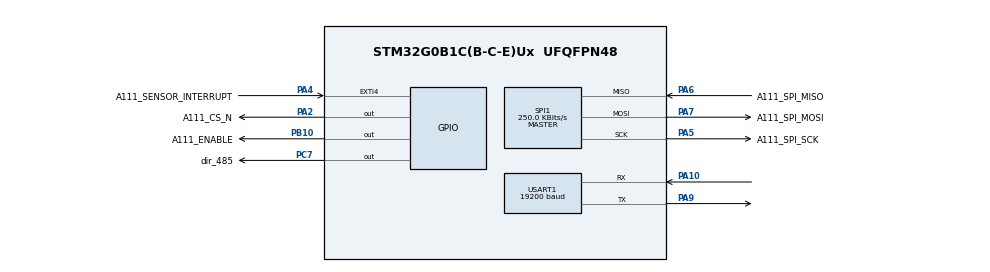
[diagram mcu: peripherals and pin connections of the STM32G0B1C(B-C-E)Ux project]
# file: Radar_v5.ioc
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Mcu.Family=STM32G0
Mcu.Name=STM32G0B1C(B-C-E)Ux
Mcu.Package=UFQFPN48
NVIC.TIM15_IRQn=true\:3\:0\:true\:false\:true\:true\:true
NVIC.USART1_IRQn=true\:0\:0\:false\:false\:true\:true\:true
PA10.Mode=Asynchronous
PA10.Signal=USART1_RX
PA13.Mode=Serial_Wire
PA13.Signal=SYS_SWDIO
PA14-BOOT0.Mode=Serial_Wire
PA14-BOOT0.Signal=SYS_SWCLK
PA2.GPIO_Label=A111_CS_N
PA2.Signal=GPIO_Output
PA4.GPIO_Label=A111_SENSOR_INTERRUPT
PA4.Signal=GPXTI4
PA5.GPIO_Label=A111_SPI_SCK
PA5.Mode=Full_Duplex_Master
PA5.Signal=SPI1_SCK
PA6.GPIO_Label=A111_SPI_MISO
PA6.Mode=Full_Duplex_Master
PA6.Signal=SPI1_MISO
PA7.GPIO_Label=A111_SPI_MOSI
PA7.Mode=Full_Duplex_Master
PA7.Signal=SPI1_MOSI
PA9.GPIO_ModeDefaultPP=GPIO_MODE_AF_OD
PA9.Mode=Asynchronous
PA9.Signal=USART1_TX
PB10.GPIO_Label=A111_ENABLE
PB10.Signal=GPIO_Output
PC7.GPIO_Label=dir_485
PC7.GPIO_ModeDefaultOutputPP=GPIO_MODE_OUTPUT_OD
PC7.Signal=GPIO_Output
PF0-OSC_IN\ (PF0).Mode=HSE-External-Oscillator
PF0-OSC_IN\ (PF0).Signal=RCC_OSC_IN
PF1-OSC_OUT\ (PF1).Mode=HSE-External-Oscillator
PF1-OSC_OUT\ (PF1).Signal=RCC_OSC_OUT
ProjectManager.HeapSize=0x200
ProjectManager.StackSize=0x400
ProjectManager.TargetToolchain=STM32CubeIDE
RCC.ADCFreq_Value=64000000
RCC.AHBFreq_Value=64000000
RCC.CortexFreq_Value=64000000
RCC.EXTERNAL_CLOCK_VALUE=48000
RCC.HCLKFreq_Value=64000000
RCC.HSE_VALUE=12000000
RCC.HSI48_VALUE=48000000
RCC.HSI_VALUE=16000000
RCC.LSE_VALUE=32768
RCC.PLLN=16
RCC.PLLR=RCC_PLLR_DIV3
RCC.PLLSourceVirtual=RCC_PLLSOURCE_HSE
RCC.SYSCLKFreq_VALUE=64000000
RCC.SYSCLKSource=RCC_SYSCLKSOURCE_PLLCLK
RCC.USBFreq_Value=48000000
RCC.VCOOutputFreq_Value=192000000
SPI1.BaudRatePrescaler=SPI_BAUDRATEPRESCALER_256
SPI1.CalculateBaudRate=250.0 KBits/s
SPI1.Direction=SPI_DIRECTION_2LINES
SPI1.Mode=SPI_MODE_MASTER
SPI1.VirtualType=VM_MASTER
TIM15.Period=999
TIM15.Prescaler=63999
TIM3.Prescaler=63999
TIM6.Prescaler=63999
USART1.BaudRate=19200
USART1.VirtualMode-Asynchronous=VM_ASYNC
VP_SYS_VS_DBSignals.Mode=DisableDeadBatterySignals
VP_TIM15_VS_ClockSourceINT.Mode=Internal
VP_TIM3_VS_ClockSourceINT.Mode=Internal
VP_TIM6_VS_ClockSourceINT.Mode=Enable_Timer
board=custom

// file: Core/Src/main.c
/* USER CODE BEGIN Header */
/**
  ******************************************************************************
  * @file           : main.c
  * @brief          : Main program body
  ******************************************************************************
  * @attention
  *
  * <h2><center>&copy; Copyright (c) 2022 STMicroelectronics.
  * All rights reserved.</center></h2>
  *
  * This software component is licensed by ST under BSD 3-Clause license,
  * the "License"; You may not use this file except in compliance with the
  * License. You may obtain a copy of the License at:
  *                        opensource.org/licenses/BSD-3-Clause
  *
  ******************************************************************************
  */
/* USER CODE END Header */
#include "main.h"

SPI_HandleTypeDef hspi1;

TIM_HandleTypeDef htim3;
TIM_HandleTypeDef htim6;

void SystemClock_Config(void);
static void MX_GPIO_Init(void);
static void MX_SPI1_Init(void);
static void MX_USART1_UART_Init(void);
static void MX_TIM15_Init(void);
static void MX_TIM3_Init(void);
static void MX_TIM6_Init(void);

int main(void)
{

  /* MCU Configuration--------------------------------------------------------*/

  /* Reset of all peripherals, Initializes the Flash interface and the Systick. */
  HAL_Init();

  /* Configure the system clock */
  SystemClock_Config();

  /* Initialize all configured peripherals */
  MX_GPIO_Init();
  MX_SPI1_Init();
  MX_USART1_UART_Init();
  MX_TIM15_Init();
  MX_TIM3_Init();
  MX_TIM6_Init();
  /* USER CODE BEGIN 2 */
  my_main();
  /* USER CODE END 2 */

  /* Infinite loop */
  while (1)
  {

  }
}

void SystemClock_Config(void)
{
  LL_FLASH_SetLatency(LL_FLASH_LATENCY_2);
  while(LL_FLASH_GetLatency() != LL_FLASH_LATENCY_2)
  {
  }

  /* HSE configuration and activation */
  LL_RCC_HSE_Enable();
  while(LL_RCC_HSE_IsReady() != 1)
  {
  }

  /* Main PLL configuration and activation */
  LL_RCC_PLL_ConfigDomain_SYS(LL_RCC_PLLSOURCE_HSE, LL_RCC_PLLM_DIV_1, 16, LL_RCC_PLLR_DIV_3);
  LL_RCC_PLL_Enable();
  LL_RCC_PLL_EnableDomain_SYS();
  while(LL_RCC_PLL_IsReady() != 1)
  {
  }

  /* Set AHB prescaler*/
  LL_RCC_SetAHBPrescaler(LL_RCC_SYSCLK_DIV_1);

  /* Sysclk activation on the main PLL */
  LL_RCC_SetSysClkSource(LL_RCC_SYS_CLKSOURCE_PLL);
  while(LL_RCC_GetSysClkSource() != LL_RCC_SYS_CLKSOURCE_STATUS_PLL)
  {
  }

  /* Set APB1 prescaler*/
  LL_RCC_SetAPB1Prescaler(LL_RCC_APB1_DIV_1);
  /* Update CMSIS variable (which can be updated also through SystemCoreClockUpdate function) */
  LL_SetSystemCoreClock(64000000);

   /* Update the time base */
  if (HAL_InitTick (TICK_INT_PRIORITY) != HAL_OK)
  {
    Error_Handler();
  }
  LL_RCC_SetTIMClockSource(LL_RCC_TIM15_CLKSOURCE_PCLK1);
  LL_RCC_SetUSARTClockSource(LL_RCC_USART1_CLKSOURCE_PCLK1);
}

static void MX_SPI1_Init(void)
{

  /* SPI1 parameter configuration*/
  hspi1.Instance = SPI1;
  hspi1.Init.Mode = SPI_MODE_MASTER;
  hspi1.Init.Direction = SPI_DIRECTION_2LINES;
  hspi1.Init.DataSize = SPI_DATASIZE_8BIT;
  hspi1.Init.CLKPolarity = SPI_POLARITY_LOW;
  hspi1.Init.CLKPhase = SPI_PHASE_1EDGE;
  hspi1.Init.NSS = SPI_NSS_SOFT;
  hspi1.Init.BaudRatePrescaler = SPI_BAUDRATEPRESCALER_256;
  hspi1.Init.FirstBit = SPI_FIRSTBIT_MSB;
  hspi1.Init.TIMode = SPI_TIMODE_DISABLE;
  hspi1.Init.CRCCalculation = SPI_CRCCALCULATION_DISABLE;
  hspi1.Init.CRCPolynomial = 7;
  hspi1.Init.CRCLength = SPI_CRC_LENGTH_DATASIZE;
  hspi1.Init.NSSPMode = SPI_NSS_PULSE_ENABLE;
  if (HAL_SPI_Init(&hspi1) != HAL_OK)
  {
    Error_Handler();
  }

}

static void MX_TIM3_Init(void)
{

  TIM_ClockConfigTypeDef sClockSourceConfig = {0};
  TIM_MasterConfigTypeDef sMasterConfig = {0};

  htim3.Instance = TIM3;
  htim3.Init.Prescaler = 63999;
  htim3.Init.CounterMode = TIM_COUNTERMODE_UP;
  htim3.Init.Period = 65535;
  htim3.Init.ClockDivision = TIM_CLOCKDIVISION_DIV1;
  htim3.Init.AutoReloadPreload = TIM_AUTORELOAD_PRELOAD_DISABLE;
  if (HAL_TIM_Base_Init(&htim3) != HAL_OK)
  {
    Error_Handler();
  }
  sClockSourceConfig.ClockSource = TIM_CLOCKSOURCE_INTERNAL;
  if (HAL_TIM_ConfigClockSource(&htim3, &sClockSourceConfig) != HAL_OK)
  {
    Error_Handler();
  }
  sMasterConfig.MasterOutputTrigger = TIM_TRGO_RESET;
  sMasterConfig.MasterSlaveMode = TIM_MASTERSLAVEMODE_DISABLE;
  if (HAL_TIMEx_MasterConfigSynchronization(&htim3, &sMasterConfig) != HAL_OK)
  {
    Error_Handler();
  }

}

static void MX_TIM6_Init(void)
{

  TIM_MasterConfigTypeDef sMasterConfig = {0};

  htim6.Instance = TIM6;
  htim6.Init.Prescaler = 63999;
  htim6.Init.CounterMode = TIM_COUNTERMODE_UP;
  htim6.Init.Period = 65535;
  htim6.Init.AutoReloadPreload = TIM_AUTORELOAD_PRELOAD_DISABLE;
  if (HAL_TIM_Base_Init(&htim6) != HAL_OK)
  {
    Error_Handler();
  }
  sMasterConfig.MasterOutputTrigger = TIM_TRGO_RESET;
  sMasterConfig.MasterSlaveMode = TIM_MASTERSLAVEMODE_DISABLE;
  if (HAL_TIMEx_MasterConfigSynchronization(&htim6, &sMasterConfig) != HAL_OK)
  {
    Error_Handler();
  }

}

static void MX_TIM15_Init(void)
{

  LL_TIM_InitTypeDef TIM_InitStruct = {0};

  /* Peripheral clock enable */
  LL_APB2_GRP1_EnableClock(LL_APB2_GRP1_PERIPH_TIM15);

  /* TIM15 interrupt Init */
  NVIC_SetPriority(TIM15_IRQn, 3);
  NVIC_EnableIRQ(TIM15_IRQn);

  TIM_InitStruct.Prescaler = 63999;
  TIM_InitStruct.CounterMode = LL_TIM_COUNTERMODE_UP;
  TIM_InitStruct.Autoreload = 999;
  TIM_InitStruct.ClockDivision = LL_TIM_CLOCKDIVISION_DIV1;
  TIM_InitStruct.RepetitionCounter = 0;
  LL_TIM_Init(TIM15, &TIM_InitStruct);
  LL_TIM_DisableARRPreload(TIM15);
  LL_TIM_SetClockSource(TIM15, LL_TIM_CLOCKSOURCE_INTERNAL);
  LL_TIM_SetTriggerOutput(TIM15, LL_TIM_TRGO_RESET);
  LL_TIM_DisableMasterSlaveMode(TIM15);

}

static void MX_USART1_UART_Init(void)
{

  LL_USART_InitTypeDef USART_InitStruct = {0};

  LL_GPIO_InitTypeDef GPIO_InitStruct = {0};

  /* Peripheral clock enable */
  LL_APB2_GRP1_EnableClock(LL_APB2_GRP1_PERIPH_USART1);

  LL_IOP_GRP1_EnableClock(LL_IOP_GRP1_PERIPH_GPIOA);
  /**USART1 GPIO Configuration
  PA9   ------> USART1_TX
  PA10   ------> USART1_RX
  */
  GPIO_InitStruct.Pin = LL_GPIO_PIN_9;
  GPIO_InitStruct.Mode = LL_GPIO_MODE_ALTERNATE;
  GPIO_InitStruct.Speed = LL_GPIO_SPEED_FREQ_LOW;
  GPIO_InitStruct.OutputType = LL_GPIO_OUTPUT_OPENDRAIN;
  GPIO_InitStruct.Pull = LL_GPIO_PULL_NO;
  GPIO_InitStruct.Alternate = LL_GPIO_AF_1;
  LL_GPIO_Init(GPIOA, &GPIO_InitStruct);

  GPIO_InitStruct.Pin = LL_GPIO_PIN_10;
  GPIO_InitStruct.Mode = LL_GPIO_MODE_ALTERNATE;
  GPIO_InitStruct.Speed = LL_GPIO_SPEED_FREQ_LOW;
  GPIO_InitStruct.OutputType = LL_GPIO_OUTPUT_PUSHPULL;
  GPIO_InitStruct.Pull = LL_GPIO_PULL_NO;
  GPIO_InitStruct.Alternate = LL_GPIO_AF_1;
  LL_GPIO_Init(GPIOA, &GPIO_InitStruct);

  /* USART1 interrupt Init */
  NVIC_SetPriority(USART1_IRQn, 0);
  NVIC_EnableIRQ(USART1_IRQn);

  USART_InitStruct.PrescalerValue = LL_USART_PRESCALER_DIV1;
  USART_InitStruct.BaudRate = 19200;
  USART_InitStruct.DataWidth = LL_USART_DATAWIDTH_8B;
  USART_InitStruct.StopBits = LL_USART_STOPBITS_1;
  USART_InitStruct.Parity = LL_USART_PARITY_NONE;
  USART_InitStruct.TransferDirection = LL_USART_DIRECTION_TX_RX;
  USART_InitStruct.HardwareFlowControl = LL_USART_HWCONTROL_NONE;
  USART_InitStruct.OverSampling = LL_USART_OVERSAMPLING_16;
  LL_USART_Init(USART1, &USART_InitStruct);
  LL_USART_SetTXFIFOThreshold(USART1, LL_USART_FIFOTHRESHOLD_1_8);
  LL_USART_SetRXFIFOThreshold(USART1, LL_USART_FIFOTHRESHOLD_1_8);
  LL_USART_DisableFIFO(USART1);
  LL_USART_ConfigAsyncMode(USART1);

  LL_USART_Enable(USART1);

  /* Polling USART1 initialisation */
  while((!(LL_USART_IsActiveFlag_TEACK(USART1))) || (!(LL_USART_IsActiveFlag_REACK(USART1))))
  {
  }

}

static void MX_GPIO_Init(void)
{
  LL_EXTI_InitTypeDef EXTI_InitStruct = {0};
  LL_GPIO_InitTypeDef GPIO_InitStruct = {0};

  /* GPIO Ports Clock Enable */
  LL_IOP_GRP1_EnableClock(LL_IOP_GRP1_PERIPH_GPIOF);
  LL_IOP_GRP1_EnableClock(LL_IOP_GRP1_PERIPH_GPIOA);
  LL_IOP_GRP1_EnableClock(LL_IOP_GRP1_PERIPH_GPIOB);
  LL_IOP_GRP1_EnableClock(LL_IOP_GRP1_PERIPH_GPIOC);

  /**/
  LL_GPIO_ResetOutputPin(A111_CS_N_GPIO_Port, A111_CS_N_Pin);

  /**/
  LL_GPIO_ResetOutputPin(A111_ENABLE_GPIO_Port, A111_ENABLE_Pin);

  /**/
  LL_GPIO_ResetOutputPin(dir_485_GPIO_Port, dir_485_Pin);

  /**/
  GPIO_InitStruct.Pin = A111_CS_N_Pin;
  GPIO_InitStruct.Mode = LL_GPIO_MODE_OUTPUT;
  GPIO_InitStruct.Speed = LL_GPIO_SPEED_FREQ_LOW;
  GPIO_InitStruct.OutputType = LL_GPIO_OUTPUT_PUSHPULL;
  GPIO_InitStruct.Pull = LL_GPIO_PULL_NO;
  LL_GPIO_Init(A111_CS_N_GPIO_Port, &GPIO_InitStruct);

  /**/
  GPIO_InitStruct.Pin = A111_ENABLE_Pin;
  GPIO_InitStruct.Mode = LL_GPIO_MODE_OUTPUT;
  GPIO_InitStruct.Speed = LL_GPIO_SPEED_FREQ_LOW;
  GPIO_InitStruct.OutputType = LL_GPIO_OUTPUT_PUSHPULL;
  GPIO_InitStruct.Pull = LL_GPIO_PULL_NO;
  LL_GPIO_Init(A111_ENABLE_GPIO_Port, &GPIO_InitStruct);

  /**/
  GPIO_InitStruct.Pin = dir_485_Pin;
  GPIO_InitStruct.Mode = LL_GPIO_MODE_OUTPUT;
  GPIO_InitStruct.Speed = LL_GPIO_SPEED_FREQ_LOW;
  GPIO_InitStruct.OutputType = LL_GPIO_OUTPUT_OPENDRAIN;
  GPIO_InitStruct.Pull = LL_GPIO_PULL_NO;
  LL_GPIO_Init(dir_485_GPIO_Port, &GPIO_InitStruct);

  /**/
  LL_EXTI_SetEXTISource(LL_EXTI_CONFIG_PORTA, LL_EXTI_CONFIG_LINE4);

  /**/
  EXTI_InitStruct.Line_0_31 = LL_EXTI_LINE_4;
  EXTI_InitStruct.LineCommand = ENABLE;
  EXTI_InitStruct.Mode = LL_EXTI_MODE_IT;
  EXTI_InitStruct.Trigger = LL_EXTI_TRIGGER_RISING;
  LL_EXTI_Init(&EXTI_InitStruct);

  /**/
  LL_GPIO_SetPinPull(A111_SENSOR_INTERRUPT_GPIO_Port, A111_SENSOR_INTERRUPT_Pin, LL_GPIO_PULL_NO);

  /**/
  LL_GPIO_SetPinMode(A111_SENSOR_INTERRUPT_GPIO_Port, A111_SENSOR_INTERRUPT_Pin, LL_GPIO_MODE_INPUT);

}

void Error_Handler(void)
{
  __disable_irq();
  while (1)
  {
  }
}

/************************ (C) COPYRIGHT STMicroelectronics *****END OF FILE****/
